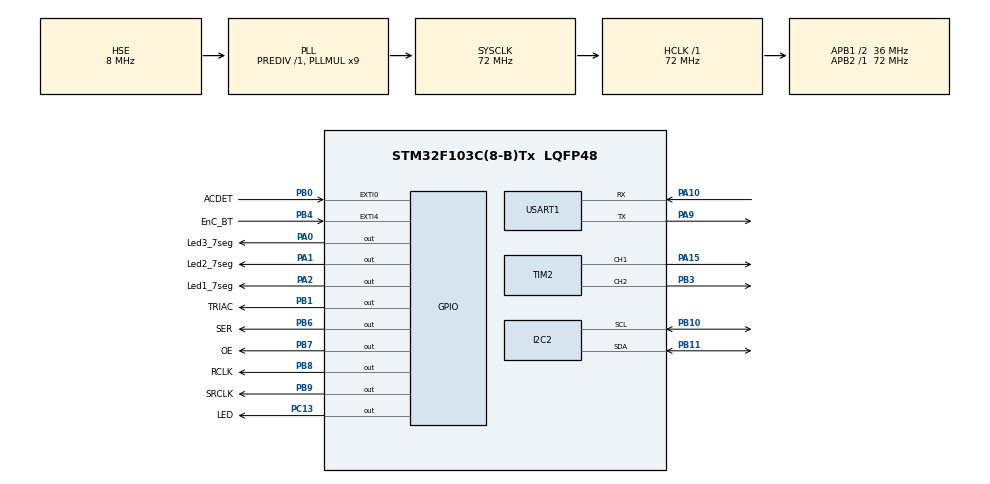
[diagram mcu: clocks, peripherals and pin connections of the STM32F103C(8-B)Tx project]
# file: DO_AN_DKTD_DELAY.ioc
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Mcu.Family=STM32F1
Mcu.Name=STM32F103C(8-B)Tx
Mcu.Package=LQFP48
NVIC.EXTI0_IRQn=true\:0\:0\:false\:false\:true\:true\:true\:true
NVIC.EXTI4_IRQn=true\:0\:0\:false\:false\:true\:true\:true\:true
NVIC.PriorityGroup=NVIC_PRIORITYGROUP_4
NVIC.TIM1_UP_IRQn=true\:0\:0\:false\:false\:true\:true\:true\:true
NVIC.TIM2_IRQn=true\:0\:0\:false\:false\:true\:true\:true\:true
NVIC.TIM3_IRQn=true\:0\:0\:false\:false\:true\:true\:true\:true
NVIC.TIM4_IRQn=true\:0\:0\:false\:false\:true\:true\:true\:true
PA0-WKUP.GPIO_Label=Led3_7seg
PA0-WKUP.GPIO_Speed=GPIO_SPEED_FREQ_HIGH
PA0-WKUP.Signal=GPIO_Output
PA1.GPIO_Label=Led2_7seg
PA1.GPIO_Speed=GPIO_SPEED_FREQ_HIGH
PA1.Signal=GPIO_Output
PA10.Mode=Asynchronous
PA10.Signal=USART1_RX
PA13.Mode=Serial_Wire
PA13.Signal=SYS_JTMS-SWDIO
PA14.Mode=Serial_Wire
PA14.Signal=SYS_JTCK-SWCLK
PA15.Signal=S_TIM2_CH1_ETR
PA2.GPIO_Label=Led1_7seg
PA2.GPIO_Speed=GPIO_SPEED_FREQ_HIGH
PA2.Signal=GPIO_Output
PA9.Mode=Asynchronous
PA9.Signal=USART1_TX
PB0.GPIO_Label=ACDET
PB0.Signal=GPXTI0
PB1.GPIO_Label=TRIAC
PB1.GPIO_Speed=GPIO_SPEED_FREQ_HIGH
PB1.Signal=GPIO_Output
PB10.Mode=I2C
PB10.Signal=I2C2_SCL
PB11.Mode=I2C
PB11.Signal=I2C2_SDA
PB3.Signal=S_TIM2_CH2
PB4.GPIO_Label=EnC_BT
PB4.Signal=GPXTI4
PB6.GPIO_Label=SER
PB6.GPIO_ModeDefaultOutputPP=GPIO_MODE_OUTPUT_OD
PB6.GPIO_PuPd=GPIO_NOPULL
PB6.GPIO_Speed=GPIO_SPEED_FREQ_HIGH
PB6.Signal=GPIO_Output
PB7.GPIO_Label=OE
PB7.GPIO_ModeDefaultOutputPP=GPIO_MODE_OUTPUT_OD
PB7.GPIO_PuPd=GPIO_NOPULL
PB7.GPIO_Speed=GPIO_SPEED_FREQ_HIGH
PB7.Signal=GPIO_Output
PB8.GPIO_Label=RCLK
PB8.GPIO_ModeDefaultOutputPP=GPIO_MODE_OUTPUT_OD
PB8.GPIO_PuPd=GPIO_NOPULL
PB8.GPIO_Speed=GPIO_SPEED_FREQ_HIGH
PB8.Signal=GPIO_Output
PB9.GPIO_Label=SRCLK
PB9.GPIO_ModeDefaultOutputPP=GPIO_MODE_OUTPUT_OD
PB9.GPIO_PuPd=GPIO_NOPULL
PB9.GPIO_Speed=GPIO_SPEED_FREQ_HIGH
PB9.Signal=GPIO_Output
PC13-TAMPER-RTC.GPIO_Label=LED
PC13-TAMPER-RTC.GPIO_Speed=GPIO_SPEED_FREQ_HIGH
PC13-TAMPER-RTC.Signal=GPIO_Output
PD0-OSC_IN.Mode=HSE-External-Oscillator
PD0-OSC_IN.Signal=RCC_OSC_IN
PD1-OSC_OUT.Mode=HSE-External-Oscillator
PD1-OSC_OUT.Signal=RCC_OSC_OUT
ProjectManager.HeapSize=0x200
ProjectManager.StackSize=0x400
ProjectManager.TargetToolchain=STM32CubeIDE
RCC.AHBFreq_Value=72000000
RCC.APB1CLKDivider=RCC_HCLK_DIV2
RCC.APB1Freq_Value=36000000
RCC.APB1TimFreq_Value=72000000
RCC.APB2Freq_Value=72000000
RCC.APB2TimFreq_Value=72000000
RCC.HCLKFreq_Value=72000000
RCC.PLLMUL=RCC_PLL_MUL9
RCC.PLLSourceVirtual=RCC_PLLSOURCE_HSE
RCC.SYSCLKFreq_VALUE=72000000
RCC.SYSCLKSource=RCC_SYSCLKSOURCE_PLLCLK
RCC.USBFreq_Value=72000000
SH.S_TIM2_CH1_ETR.0=TIM2_CH1,Output Compare1 CH1
SH.S_TIM2_CH2.0=TIM2_CH2,Output Compare2 CH2
TIM1.Prescaler=72 - 1
TIM2.Channel-Output\ Compare1\ CH1=TIM_CHANNEL_1
TIM2.Channel-Output\ Compare2\ CH2=TIM_CHANNEL_2
TIM3.Prescaler=72 - 1
TIM4.Prescaler=72 - 1
USART1.VirtualMode=VM_ASYNC
VP_TIM1_VS_ClockSourceINT.Mode=Internal
VP_TIM3_VS_ClockSourceINT.Mode=Internal
VP_TIM4_VS_ClockSourceINT.Mode=Internal
board=custom

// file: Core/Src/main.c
/* USER CODE BEGIN Header */
/**
  ******************************************************************************
  * @file           : main.c
  * @brief          : Main program body
  ******************************************************************************
  * @attention
  *
  * Copyright (c) 2023 STMicroelectronics.
  * All rights reserved.
  *
  * This software is licensed under terms that can be found in the LICENSE file
  * in the root directory of this software component.
  * If no LICENSE file comes with this software, it is provided AS-IS.
  *
  ******************************************************************************
  */
/* USER CODE END Header */
#include "main.h"

/* USER CODE BEGIN Includes */
#include <stdio.h>
#include "SHT32.h"
/* USER CODE END Includes */

I2C_HandleTypeDef hi2c2;

TIM_HandleTypeDef htim1;
TIM_HandleTypeDef htim2;
TIM_HandleTypeDef htim3;
TIM_HandleTypeDef htim4;

UART_HandleTypeDef huart1;

void SystemClock_Config(void);
static void MX_GPIO_Init(void);
static void MX_I2C2_Init(void);
static void MX_TIM1_Init(void);
static void MX_TIM2_Init(void);
static void MX_TIM3_Init(void);
static void MX_TIM4_Init(void);
static void MX_USART1_UART_Init(void);

int main(void)
{

  /* MCU Configuration--------------------------------------------------------*/

  /* Reset of all peripherals, Initializes the Flash interface and the Systick. */
  HAL_Init();

  /* Configure the system clock */
  SystemClock_Config();

  /* Initialize all configured peripherals */
  MX_GPIO_Init();
  MX_I2C2_Init();
  MX_TIM1_Init();
  MX_TIM2_Init();
  MX_TIM3_Init();
  MX_TIM4_Init();
  MX_USART1_UART_Init();

  /* Infinite loop */
  while (1)
  {

  }
}

void SystemClock_Config(void)
{
  RCC_OscInitTypeDef RCC_OscInitStruct = {0};
  RCC_ClkInitTypeDef RCC_ClkInitStruct = {0};

  /** Initializes the RCC Oscillators according to the specified parameters
  * in the RCC_OscInitTypeDef structure.
  */
  RCC_OscInitStruct.OscillatorType = RCC_OSCILLATORTYPE_HSE;
  RCC_OscInitStruct.HSEState = RCC_HSE_ON;
  RCC_OscInitStruct.HSEPredivValue = RCC_HSE_PREDIV_DIV1;
  RCC_OscInitStruct.HSIState = RCC_HSI_ON;
  RCC_OscInitStruct.PLL.PLLState = RCC_PLL_ON;
  RCC_OscInitStruct.PLL.PLLSource = RCC_PLLSOURCE_HSE;
  RCC_OscInitStruct.PLL.PLLMUL = RCC_PLL_MUL9;
  if (HAL_RCC_OscConfig(&RCC_OscInitStruct) != HAL_OK)
  {
    Error_Handler();
  }

  /** Initializes the CPU, AHB and APB buses clocks
  */
  RCC_ClkInitStruct.ClockType = RCC_CLOCKTYPE_HCLK|RCC_CLOCKTYPE_SYSCLK
                              |RCC_CLOCKTYPE_PCLK1|RCC_CLOCKTYPE_PCLK2;
  RCC_ClkInitStruct.SYSCLKSource = RCC_SYSCLKSOURCE_PLLCLK;
  RCC_ClkInitStruct.AHBCLKDivider = RCC_SYSCLK_DIV1;
  RCC_ClkInitStruct.APB1CLKDivider = RCC_HCLK_DIV2;
  RCC_ClkInitStruct.APB2CLKDivider = RCC_HCLK_DIV1;

  if (HAL_RCC_ClockConfig(&RCC_ClkInitStruct, FLASH_LATENCY_2) != HAL_OK)
  {
    Error_Handler();
  }
}

static void MX_I2C2_Init(void)
{

  hi2c2.Instance = I2C2;
  hi2c2.Init.ClockSpeed = 100000;
  hi2c2.Init.DutyCycle = I2C_DUTYCYCLE_2;
  hi2c2.Init.OwnAddress1 = 0;
  hi2c2.Init.AddressingMode = I2C_ADDRESSINGMODE_7BIT;
  hi2c2.Init.DualAddressMode = I2C_DUALADDRESS_DISABLE;
  hi2c2.Init.OwnAddress2 = 0;
  hi2c2.Init.GeneralCallMode = I2C_GENERALCALL_DISABLE;
  hi2c2.Init.NoStretchMode = I2C_NOSTRETCH_DISABLE;
  if (HAL_I2C_Init(&hi2c2) != HAL_OK)
  {
    Error_Handler();
  }

}

static void MX_TIM1_Init(void)
{

  TIM_ClockConfigTypeDef sClockSourceConfig = {0};
  TIM_MasterConfigTypeDef sMasterConfig = {0};

  htim1.Instance = TIM1;
  htim1.Init.Prescaler = 72 - 1;
  htim1.Init.CounterMode = TIM_COUNTERMODE_UP;
  htim1.Init.Period = 65535;
  htim1.Init.ClockDivision = TIM_CLOCKDIVISION_DIV1;
  htim1.Init.RepetitionCounter = 0;
  htim1.Init.AutoReloadPreload = TIM_AUTORELOAD_PRELOAD_DISABLE;
  if (HAL_TIM_Base_Init(&htim1) != HAL_OK)
  {
    Error_Handler();
  }
  sClockSourceConfig.ClockSource = TIM_CLOCKSOURCE_INTERNAL;
  if (HAL_TIM_ConfigClockSource(&htim1, &sClockSourceConfig) != HAL_OK)
  {
    Error_Handler();
  }
  sMasterConfig.MasterOutputTrigger = TIM_TRGO_RESET;
  sMasterConfig.MasterSlaveMode = TIM_MASTERSLAVEMODE_DISABLE;
  if (HAL_TIMEx_MasterConfigSynchronization(&htim1, &sMasterConfig) != HAL_OK)
  {
    Error_Handler();
  }

}

static void MX_TIM2_Init(void)
{

  TIM_MasterConfigTypeDef sMasterConfig = {0};
  TIM_OC_InitTypeDef sConfigOC = {0};

  htim2.Instance = TIM2;
  htim2.Init.Prescaler = 0;
  htim2.Init.CounterMode = TIM_COUNTERMODE_UP;
  htim2.Init.Period = 65535;
  htim2.Init.ClockDivision = TIM_CLOCKDIVISION_DIV1;
  htim2.Init.AutoReloadPreload = TIM_AUTORELOAD_PRELOAD_DISABLE;
  if (HAL_TIM_OC_Init(&htim2) != HAL_OK)
  {
    Error_Handler();
  }
  sMasterConfig.MasterOutputTrigger = TIM_TRGO_RESET;
  sMasterConfig.MasterSlaveMode = TIM_MASTERSLAVEMODE_DISABLE;
  if (HAL_TIMEx_MasterConfigSynchronization(&htim2, &sMasterConfig) != HAL_OK)
  {
    Error_Handler();
  }
  sConfigOC.OCMode = TIM_OCMODE_TIMING;
  sConfigOC.Pulse = 0;
  sConfigOC.OCPolarity = TIM_OCPOLARITY_HIGH;
  sConfigOC.OCFastMode = TIM_OCFAST_DISABLE;
  if (HAL_TIM_OC_ConfigChannel(&htim2, &sConfigOC, TIM_CHANNEL_1) != HAL_OK)
  {
    Error_Handler();
  }
  if (HAL_TIM_OC_ConfigChannel(&htim2, &sConfigOC, TIM_CHANNEL_2) != HAL_OK)
  {
    Error_Handler();
  }
  HAL_TIM_MspPostInit(&htim2);

}

static void MX_TIM3_Init(void)
{

  TIM_ClockConfigTypeDef sClockSourceConfig = {0};
  TIM_MasterConfigTypeDef sMasterConfig = {0};

  htim3.Instance = TIM3;
  htim3.Init.Prescaler = 72 - 1;
  htim3.Init.CounterMode = TIM_COUNTERMODE_UP;
  htim3.Init.Period = 65535;
  htim3.Init.ClockDivision = TIM_CLOCKDIVISION_DIV1;
  htim3.Init.AutoReloadPreload = TIM_AUTORELOAD_PRELOAD_DISABLE;
  if (HAL_TIM_Base_Init(&htim3) != HAL_OK)
  {
    Error_Handler();
  }
  sClockSourceConfig.ClockSource = TIM_CLOCKSOURCE_INTERNAL;
  if (HAL_TIM_ConfigClockSource(&htim3, &sClockSourceConfig) != HAL_OK)
  {
    Error_Handler();
  }
  sMasterConfig.MasterOutputTrigger = TIM_TRGO_RESET;
  sMasterConfig.MasterSlaveMode = TIM_MASTERSLAVEMODE_DISABLE;
  if (HAL_TIMEx_MasterConfigSynchronization(&htim3, &sMasterConfig) != HAL_OK)
  {
    Error_Handler();
  }

}

static void MX_TIM4_Init(void)
{

  TIM_ClockConfigTypeDef sClockSourceConfig = {0};
  TIM_MasterConfigTypeDef sMasterConfig = {0};

  htim4.Instance = TIM4;
  htim4.Init.Prescaler = 72 - 1;
  htim4.Init.CounterMode = TIM_COUNTERMODE_UP;
  htim4.Init.Period = 65535;
  htim4.Init.ClockDivision = TIM_CLOCKDIVISION_DIV1;
  htim4.Init.AutoReloadPreload = TIM_AUTORELOAD_PRELOAD_DISABLE;
  if (HAL_TIM_Base_Init(&htim4) != HAL_OK)
  {
    Error_Handler();
  }
  sClockSourceConfig.ClockSource = TIM_CLOCKSOURCE_INTERNAL;
  if (HAL_TIM_ConfigClockSource(&htim4, &sClockSourceConfig) != HAL_OK)
  {
    Error_Handler();
  }
  sMasterConfig.MasterOutputTrigger = TIM_TRGO_RESET;
  sMasterConfig.MasterSlaveMode = TIM_MASTERSLAVEMODE_DISABLE;
  if (HAL_TIMEx_MasterConfigSynchronization(&htim4, &sMasterConfig) != HAL_OK)
  {
    Error_Handler();
  }

}

static void MX_USART1_UART_Init(void)
{

  huart1.Instance = USART1;
  huart1.Init.BaudRate = 115200;
  huart1.Init.WordLength = UART_WORDLENGTH_8B;
  huart1.Init.StopBits = UART_STOPBITS_1;
  huart1.Init.Parity = UART_PARITY_NONE;
  huart1.Init.Mode = UART_MODE_TX_RX;
  huart1.Init.HwFlowCtl = UART_HWCONTROL_NONE;
  huart1.Init.OverSampling = UART_OVERSAMPLING_16;
  if (HAL_UART_Init(&huart1) != HAL_OK)
  {
    Error_Handler();
  }

}

static void MX_GPIO_Init(void)
{
  GPIO_InitTypeDef GPIO_InitStruct = {0};

  /* GPIO Ports Clock Enable */
  __HAL_RCC_GPIOC_CLK_ENABLE();
  __HAL_RCC_GPIOD_CLK_ENABLE();
  __HAL_RCC_GPIOA_CLK_ENABLE();
  __HAL_RCC_GPIOB_CLK_ENABLE();

  /*Configure GPIO pin Output Level */
  HAL_GPIO_WritePin(LED_GPIO_Port, LED_Pin, GPIO_PIN_RESET);

  /*Configure GPIO pin Output Level */
  HAL_GPIO_WritePin(GPIOA, Led3_7seg_Pin|Led2_7seg_Pin|Led1_7seg_Pin, GPIO_PIN_RESET);

  /*Configure GPIO pin Output Level */
  HAL_GPIO_WritePin(GPIOB, TRIAC_Pin|SER_Pin|OE_Pin|RCLK_Pin
                          |SRCLK_Pin, GPIO_PIN_RESET);

  /*Configure GPIO pin : LED_Pin */
  GPIO_InitStruct.Pin = LED_Pin;
  GPIO_InitStruct.Mode = GPIO_MODE_OUTPUT_PP;
  GPIO_InitStruct.Pull = GPIO_NOPULL;
  GPIO_InitStruct.Speed = GPIO_SPEED_FREQ_HIGH;
  HAL_GPIO_Init(LED_GPIO_Port, &GPIO_InitStruct);

  /*Configure GPIO pins : Led3_7seg_Pin Led2_7seg_Pin Led1_7seg_Pin */
  GPIO_InitStruct.Pin = Led3_7seg_Pin|Led2_7seg_Pin|Led1_7seg_Pin;
  GPIO_InitStruct.Mode = GPIO_MODE_OUTPUT_PP;
  GPIO_InitStruct.Pull = GPIO_NOPULL;
  GPIO_InitStruct.Speed = GPIO_SPEED_FREQ_HIGH;
  HAL_GPIO_Init(GPIOA, &GPIO_InitStruct);

  /*Configure GPIO pins : ACDET_Pin EnC_BT_Pin */
  GPIO_InitStruct.Pin = ACDET_Pin|EnC_BT_Pin;
  GPIO_InitStruct.Mode = GPIO_MODE_IT_RISING;
  GPIO_InitStruct.Pull = GPIO_NOPULL;
  HAL_GPIO_Init(GPIOB, &GPIO_InitStruct);

  /*Configure GPIO pin : TRIAC_Pin */
  GPIO_InitStruct.Pin = TRIAC_Pin;
  GPIO_InitStruct.Mode = GPIO_MODE_OUTPUT_PP;
  GPIO_InitStruct.Pull = GPIO_NOPULL;
  GPIO_InitStruct.Speed = GPIO_SPEED_FREQ_HIGH;
  HAL_GPIO_Init(TRIAC_GPIO_Port, &GPIO_InitStruct);

  /*Configure GPIO pins : SER_Pin OE_Pin RCLK_Pin SRCLK_Pin */
  GPIO_InitStruct.Pin = SER_Pin|OE_Pin|RCLK_Pin|SRCLK_Pin;
  GPIO_InitStruct.Mode = GPIO_MODE_OUTPUT_OD;
  GPIO_InitStruct.Pull = GPIO_NOPULL;
  GPIO_InitStruct.Speed = GPIO_SPEED_FREQ_HIGH;
  HAL_GPIO_Init(GPIOB, &GPIO_InitStruct);

  /* EXTI interrupt init*/
  HAL_NVIC_SetPriority(EXTI0_IRQn, 0, 0);
  HAL_NVIC_EnableIRQ(EXTI0_IRQn);

  HAL_NVIC_SetPriority(EXTI4_IRQn, 0, 0);
  HAL_NVIC_EnableIRQ(EXTI4_IRQn);

}

void Error_Handler(void)
{
  __disable_irq();
  while (1)
  {
  }
}
